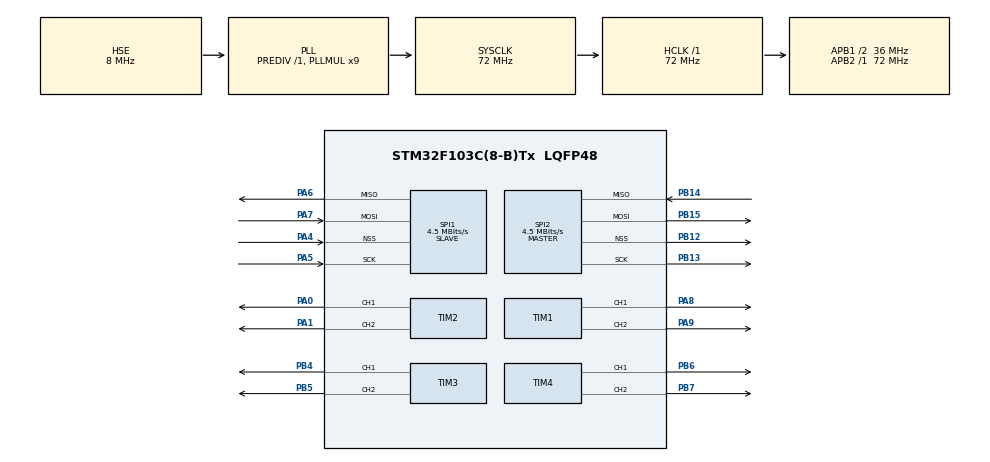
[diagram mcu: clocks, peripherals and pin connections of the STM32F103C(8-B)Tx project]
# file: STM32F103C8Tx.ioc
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Dma.Request0=TIM3_CH1/TRIG
Dma.Request1=TIM4_CH1
Dma.Request2=TIM2_CH1
Dma.Request3=TIM1_CH1
Dma.TIM1_CH1.3.Direction=DMA_MEMORY_TO_PERIPH
Dma.TIM1_CH1.3.Instance=DMA1_Channel2
Dma.TIM1_CH1.3.MemDataAlignment=DMA_MDATAALIGN_BYTE
Dma.TIM1_CH1.3.MemInc=DMA_MINC_ENABLE
Dma.TIM1_CH1.3.Mode=DMA_NORMAL
Dma.TIM1_CH1.3.PeriphDataAlignment=DMA_PDATAALIGN_BYTE
Dma.TIM1_CH1.3.PeriphInc=DMA_PINC_DISABLE
Dma.TIM1_CH1.3.Priority=DMA_PRIORITY_VERY_HIGH
Dma.TIM2_CH1.2.Direction=DMA_MEMORY_TO_PERIPH
Dma.TIM2_CH1.2.Instance=DMA1_Channel5
Dma.TIM2_CH1.2.MemDataAlignment=DMA_MDATAALIGN_BYTE
Dma.TIM2_CH1.2.MemInc=DMA_MINC_ENABLE
Dma.TIM2_CH1.2.Mode=DMA_NORMAL
Dma.TIM2_CH1.2.PeriphDataAlignment=DMA_PDATAALIGN_BYTE
Dma.TIM2_CH1.2.PeriphInc=DMA_PINC_DISABLE
Dma.TIM2_CH1.2.Priority=DMA_PRIORITY_HIGH
Dma.TIM3_CH1/TRIG.0.Direction=DMA_MEMORY_TO_PERIPH
Dma.TIM3_CH1/TRIG.0.Instance=DMA1_Channel6
Dma.TIM3_CH1/TRIG.0.MemDataAlignment=DMA_MDATAALIGN_BYTE
Dma.TIM3_CH1/TRIG.0.MemInc=DMA_MINC_ENABLE
Dma.TIM3_CH1/TRIG.0.Mode=DMA_NORMAL
Dma.TIM3_CH1/TRIG.0.PeriphDataAlignment=DMA_PDATAALIGN_BYTE
Dma.TIM3_CH1/TRIG.0.PeriphInc=DMA_PINC_DISABLE
Dma.TIM3_CH1/TRIG.0.Priority=DMA_PRIORITY_MEDIUM
Dma.TIM4_CH1.1.Direction=DMA_MEMORY_TO_PERIPH
Dma.TIM4_CH1.1.Instance=DMA1_Channel1
Dma.TIM4_CH1.1.MemDataAlignment=DMA_MDATAALIGN_BYTE
Dma.TIM4_CH1.1.MemInc=DMA_MINC_ENABLE
Dma.TIM4_CH1.1.Mode=DMA_NORMAL
Dma.TIM4_CH1.1.PeriphDataAlignment=DMA_PDATAALIGN_BYTE
Dma.TIM4_CH1.1.PeriphInc=DMA_PINC_DISABLE
Dma.TIM4_CH1.1.Priority=DMA_PRIORITY_LOW
Mcu.Family=STM32F1
Mcu.Name=STM32F103C(8-B)Tx
Mcu.Package=LQFP48
NVIC.DMA1_Channel1_IRQn=true\:0\:0\:false\:false\:true\:true
NVIC.DMA1_Channel2_IRQn=true\:0\:0\:false\:false\:true\:true
NVIC.DMA1_Channel5_IRQn=true\:0\:0\:false\:false\:true\:true
NVIC.DMA1_Channel6_IRQn=true\:0\:0\:false\:false\:true\:true
NVIC.PriorityGroup=NVIC_PRIORITYGROUP_4
NVIC.SPI1_IRQn=true\:0\:0\:false\:false\:true\:true
NVIC.SPI2_IRQn=true\:0\:0\:false\:false\:true\:true
PA0-WKUP.Signal=S_TIM2_CH1_ETR
PA1.Signal=S_TIM2_CH2
PA13.Mode=Serial_Wire
PA13.Signal=SYS_JTMS-SWDIO
PA14.Mode=Serial_Wire
PA14.Signal=SYS_JTCK-SWCLK
PA4.GPIO_Mode=GPIO_MODE_INPUT
PA4.GPIO_PuPd=GPIO_NOPULL
PA4.Mode=NSS_Signal_Hard_Input
PA4.Signal=SPI1_NSS
PA5.GPIO_Mode=GPIO_MODE_INPUT
PA5.GPIO_PuPd=GPIO_NOPULL
PA5.Mode=Full_Duplex_Slave
PA5.Signal=SPI1_SCK
PA6.Mode=Full_Duplex_Slave
PA6.Signal=SPI1_MISO
PA7.Mode=Full_Duplex_Slave
PA7.Signal=SPI1_MOSI
PA8.Signal=S_TIM1_CH1
PA9.Signal=S_TIM1_CH2
PB12.Mode=NSS_Signal_Hard_Output
PB12.Signal=SPI2_NSS
PB13.Mode=Full_Duplex_Master
PB13.Signal=SPI2_SCK
PB14.Mode=Full_Duplex_Master
PB14.Signal=SPI2_MISO
PB15.Mode=Full_Duplex_Master
PB15.Signal=SPI2_MOSI
PB4.Signal=S_TIM3_CH1
PB5.Signal=S_TIM3_CH2
PB6.Signal=S_TIM4_CH1
PB7.Signal=S_TIM4_CH2
PD0-OSC_IN.Mode=HSE-External-Oscillator
PD0-OSC_IN.Signal=RCC_OSC_IN
PD1-OSC_OUT.Mode=HSE-External-Oscillator
PD1-OSC_OUT.Signal=RCC_OSC_OUT
ProjectManager.HeapSize=0x200
ProjectManager.StackSize=0x400
ProjectManager.TargetToolchain=SW4STM32
RCC.AHBFreq_Value=72000000
RCC.APB1CLKDivider=RCC_HCLK_DIV2
RCC.APB1Freq_Value=36000000
RCC.APB1TimFreq_Value=72000000
RCC.APB2Freq_Value=72000000
RCC.APB2TimFreq_Value=72000000
RCC.HCLKFreq_Value=72000000
RCC.PLLMUL=RCC_PLL_MUL9
RCC.PLLSourceVirtual=RCC_PLLSOURCE_HSE
RCC.SYSCLKFreq_VALUE=72000000
RCC.SYSCLKSource=RCC_SYSCLKSOURCE_PLLCLK
RCC.USBFreq_Value=72000000
SH.S_TIM1_CH1.0=TIM1_CH1,PWM Generation1 CH1
SH.S_TIM1_CH2.0=TIM1_CH2,Output Compare2 CH2
SH.S_TIM2_CH1_ETR.0=TIM2_CH1,PWM Generation1 CH1
SH.S_TIM2_CH2.0=TIM2_CH2,Output Compare2 CH2
SH.S_TIM3_CH1.0=TIM3_CH1,PWM Generation1 CH1
SH.S_TIM3_CH2.0=TIM3_CH2,Output Compare2 CH2
SH.S_TIM4_CH1.0=TIM4_CH1,PWM Generation1 CH1
SH.S_TIM4_CH2.0=TIM4_CH2,Output Compare2 CH2
SPI1.BaudRatePrescaler=SPI_BAUDRATEPRESCALER_16
SPI1.CalculateBaudRate=4.5 MBits/s
SPI1.Direction=SPI_DIRECTION_2LINES
SPI1.Mode=SPI_MODE_SLAVE
SPI1.VirtualNSS=VM_NSSHARD
SPI1.VirtualType=VM_SLAVE
SPI2.BaudRatePrescaler=SPI_BAUDRATEPRESCALER_8
SPI2.CalculateBaudRate=4.5 MBits/s
SPI2.Direction=SPI_DIRECTION_2LINES
SPI2.Mode=SPI_MODE_MASTER
SPI2.VirtualNSS=VM_NSSHARD
SPI2.VirtualType=VM_MASTER
TIM1.Channel-Output\ Compare2\ CH2=TIM_CHANNEL_2
TIM1.Channel-PWM\ Generation1\ CH1=TIM_CHANNEL_1
TIM1.OCMode_2=TIM_OCMODE_TOGGLE
TIM2.Channel-Output\ Compare2\ CH2=TIM_CHANNEL_2
TIM2.Channel-PWM\ Generation1\ CH1=TIM_CHANNEL_1
TIM2.OCMode_2=TIM_OCMODE_TOGGLE
TIM3.Channel-Output\ Compare2\ CH2=TIM_CHANNEL_2
TIM3.Channel-PWM\ Generation1\ CH1=TIM_CHANNEL_1
TIM3.OCMode_2=TIM_OCMODE_TOGGLE
TIM4.Channel-Output\ Compare2\ CH2=TIM_CHANNEL_2
TIM4.Channel-PWM\ Generation1\ CH1=TIM_CHANNEL_1
TIM4.OCMode_2=TIM_OCMODE_TOGGLE
VP_TIM1_VS_ClockSourceINT.Mode=Internal
VP_TIM2_VS_ClockSourceINT.Mode=Internal
VP_TIM3_VS_ClockSourceINT.Mode=Internal
VP_TIM4_VS_ClockSourceINT.Mode=Internal
board=STM32F103C8Tx

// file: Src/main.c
/**
  ******************************************************************************
  * File Name          : main.c
  * Description        : Main program body
  ******************************************************************************
  ** This notice applies to any and all portions of this file
  * that are not between comment pairs USER CODE BEGIN and
  * USER CODE END. Other portions of this file, whether
  * inserted by the user or by software development tools
  * are owned by their respective copyright owners.
  *
  * COPYRIGHT(c) 2017 STMicroelectronics
  *
  * Redistribution and use in source and binary forms, with or without modification,
  * are permitted provided that the following conditions are met:
  *   1. Redistributions of source code must retain the above copyright notice,
  *      this list of conditions and the following disclaimer.
  *   2. Redistributions in binary form must reproduce the above copyright notice,
  *      this list of conditions and the following disclaimer in the documentation
  *      and/or other materials provided with the distribution.
  *   3. Neither the name of STMicroelectronics nor the names of its contributors
  *      may be used to endorse or promote products derived from this software
  *      without specific prior written permission.
  *
  * THIS SOFTWARE IS PROVIDED BY THE COPYRIGHT HOLDERS AND CONTRIBUTORS "AS IS"
  * AND ANY EXPRESS OR IMPLIED WARRANTIES, INCLUDING, BUT NOT LIMITED TO, THE
  * IMPLIED WARRANTIES OF MERCHANTABILITY AND FITNESS FOR A PARTICULAR PURPOSE ARE
  * DISCLAIMED. IN NO EVENT SHALL THE COPYRIGHT HOLDER OR CONTRIBUTORS BE LIABLE
  * FOR ANY DIRECT, INDIRECT, INCIDENTAL, SPECIAL, EXEMPLARY, OR CONSEQUENTIAL
  * DAMAGES (INCLUDING, BUT NOT LIMITED TO, PROCUREMENT OF SUBSTITUTE GOODS OR
  * SERVICES; LOSS OF USE, DATA, OR PROFITS; OR BUSINESS INTERRUPTION) HOWEVER
  * CAUSED AND ON ANY THEORY OF LIABILITY, WHETHER IN CONTRACT, STRICT LIABILITY,
  * OR TORT (INCLUDING NEGLIGENCE OR OTHERWISE) ARISING IN ANY WAY OUT OF THE USE
  * OF THIS SOFTWARE, EVEN IF ADVISED OF THE POSSIBILITY OF SUCH DAMAGE.
  *
  ******************************************************************************
  */

#include "main.h"
#include "stm32f1xx_hal.h"

/* USER CODE BEGIN Includes */
#include "generator.h"
/* USER CODE END Includes */

SPI_HandleTypeDef hspi1;
SPI_HandleTypeDef hspi2;

TIM_HandleTypeDef htim1;
TIM_HandleTypeDef htim2;
TIM_HandleTypeDef htim3;
TIM_HandleTypeDef htim4;
DMA_HandleTypeDef hdma_tim1_ch1;
DMA_HandleTypeDef hdma_tim2_ch1;
DMA_HandleTypeDef hdma_tim3_ch1_trig;
DMA_HandleTypeDef hdma_tim4_ch1;

void SystemClock_Config(void);
static void MX_GPIO_Init(void);
static void MX_DMA_Init(void);
static void MX_SPI1_Init(void);
static void MX_SPI2_Init(void);
static void MX_TIM1_Init(void);
static void MX_TIM2_Init(void);
static void MX_TIM3_Init(void);
static void MX_TIM4_Init(void);

void HAL_TIM_MspPostInit(TIM_HandleTypeDef *htim);

int main(void)
{

  /* MCU Configuration----------------------------------------------------------*/

  /* Reset of all peripherals, Initializes the Flash interface and the Systick. */
  HAL_Init();

  /* Configure the system clock */
  SystemClock_Config();

  /* USER CODE BEGIN SysInit */
  // init generation core data
  GEN_system_init();
  /* USER CODE END SysInit */

  /* Initialize all configured peripherals */
  MX_GPIO_Init();
  MX_DMA_Init();
  MX_SPI1_Init();
  MX_SPI2_Init();
  MX_TIM1_Init();
  MX_TIM2_Init();
  MX_TIM3_Init();
  MX_TIM4_Init();

  /* USER CODE BEGIN 2 */
  // init generation data
  GEN_init();
  /* USER CODE END 2 */

  /* Infinite loop */
  while (1)
  {

  }

}

/** System Clock Configuration
*/
void SystemClock_Config(void)
{

  RCC_OscInitTypeDef RCC_OscInitStruct;
  RCC_ClkInitTypeDef RCC_ClkInitStruct;

    /**Initializes the CPU, AHB and APB busses clocks
    */
  RCC_OscInitStruct.OscillatorType = RCC_OSCILLATORTYPE_HSE;
  RCC_OscInitStruct.HSEState = RCC_HSE_ON;
  RCC_OscInitStruct.HSEPredivValue = RCC_HSE_PREDIV_DIV1;
  RCC_OscInitStruct.HSIState = RCC_HSI_ON;
  RCC_OscInitStruct.PLL.PLLState = RCC_PLL_ON;
  RCC_OscInitStruct.PLL.PLLSource = RCC_PLLSOURCE_HSE;
  RCC_OscInitStruct.PLL.PLLMUL = RCC_PLL_MUL9;
  if (HAL_RCC_OscConfig(&RCC_OscInitStruct) != HAL_OK)
  {
    _Error_Handler(__FILE__, __LINE__);
  }

    /**Initializes the CPU, AHB and APB busses clocks
    */
  RCC_ClkInitStruct.ClockType = RCC_CLOCKTYPE_HCLK|RCC_CLOCKTYPE_SYSCLK
                              |RCC_CLOCKTYPE_PCLK1|RCC_CLOCKTYPE_PCLK2;
  RCC_ClkInitStruct.SYSCLKSource = RCC_SYSCLKSOURCE_PLLCLK;
  RCC_ClkInitStruct.AHBCLKDivider = RCC_SYSCLK_DIV1;
  RCC_ClkInitStruct.APB1CLKDivider = RCC_HCLK_DIV2;
  RCC_ClkInitStruct.APB2CLKDivider = RCC_HCLK_DIV1;

  if (HAL_RCC_ClockConfig(&RCC_ClkInitStruct, FLASH_LATENCY_2) != HAL_OK)
  {
    _Error_Handler(__FILE__, __LINE__);
  }

    /**Configure the Systick interrupt time
    */
  HAL_SYSTICK_Config(HAL_RCC_GetHCLKFreq()/1000);

    /**Configure the Systick
    */
  HAL_SYSTICK_CLKSourceConfig(SYSTICK_CLKSOURCE_HCLK);

  /* SysTick_IRQn interrupt configuration */
  HAL_NVIC_SetPriority(SysTick_IRQn, 0, 0);
}

/* SPI1 init function */
static void MX_SPI1_Init(void)
{

  /* SPI1 parameter configuration*/
  hspi1.Instance = SPI1;
  hspi1.Init.Mode = SPI_MODE_SLAVE;
  hspi1.Init.Direction = SPI_DIRECTION_2LINES;
  hspi1.Init.DataSize = SPI_DATASIZE_8BIT;
  hspi1.Init.CLKPolarity = SPI_POLARITY_LOW;
  hspi1.Init.CLKPhase = SPI_PHASE_1EDGE;
  hspi1.Init.NSS = SPI_NSS_HARD_INPUT;
  hspi1.Init.BaudRatePrescaler = SPI_BAUDRATEPRESCALER_16;
  hspi1.Init.FirstBit = SPI_FIRSTBIT_MSB;
  hspi1.Init.TIMode = SPI_TIMODE_DISABLE;
  hspi1.Init.CRCCalculation = SPI_CRCCALCULATION_DISABLE;
  hspi1.Init.CRCPolynomial = 10;
  if (HAL_SPI_Init(&hspi1) != HAL_OK)
  {
    _Error_Handler(__FILE__, __LINE__);
  }

}

/* SPI2 init function */
static void MX_SPI2_Init(void)
{

  /* SPI2 parameter configuration*/
  hspi2.Instance = SPI2;
  hspi2.Init.Mode = SPI_MODE_MASTER;
  hspi2.Init.Direction = SPI_DIRECTION_2LINES;
  hspi2.Init.DataSize = SPI_DATASIZE_8BIT;
  hspi2.Init.CLKPolarity = SPI_POLARITY_LOW;
  hspi2.Init.CLKPhase = SPI_PHASE_1EDGE;
  hspi2.Init.NSS = SPI_NSS_HARD_OUTPUT;
  hspi2.Init.BaudRatePrescaler = SPI_BAUDRATEPRESCALER_8;
  hspi2.Init.FirstBit = SPI_FIRSTBIT_MSB;
  hspi2.Init.TIMode = SPI_TIMODE_DISABLE;
  hspi2.Init.CRCCalculation = SPI_CRCCALCULATION_DISABLE;
  hspi2.Init.CRCPolynomial = 10;
  if (HAL_SPI_Init(&hspi2) != HAL_OK)
  {
    _Error_Handler(__FILE__, __LINE__);
  }

}

/* TIM1 init function */
static void MX_TIM1_Init(void)
{

  TIM_ClockConfigTypeDef sClockSourceConfig;
  TIM_MasterConfigTypeDef sMasterConfig;
  TIM_OC_InitTypeDef sConfigOC;
  TIM_BreakDeadTimeConfigTypeDef sBreakDeadTimeConfig;

  htim1.Instance = TIM1;
  htim1.Init.Prescaler = 0;
  htim1.Init.CounterMode = TIM_COUNTERMODE_UP;
  htim1.Init.Period = 0;
  htim1.Init.ClockDivision = TIM_CLOCKDIVISION_DIV1;
  htim1.Init.RepetitionCounter = 0;
  htim1.Init.AutoReloadPreload = TIM_AUTORELOAD_PRELOAD_DISABLE;
  if (HAL_TIM_Base_Init(&htim1) != HAL_OK)
  {
    _Error_Handler(__FILE__, __LINE__);
  }

  sClockSourceConfig.ClockSource = TIM_CLOCKSOURCE_INTERNAL;
  if (HAL_TIM_ConfigClockSource(&htim1, &sClockSourceConfig) != HAL_OK)
  {
    _Error_Handler(__FILE__, __LINE__);
  }

  if (HAL_TIM_PWM_Init(&htim1) != HAL_OK)
  {
    _Error_Handler(__FILE__, __LINE__);
  }

  if (HAL_TIM_OC_Init(&htim1) != HAL_OK)
  {
    _Error_Handler(__FILE__, __LINE__);
  }

  sMasterConfig.MasterOutputTrigger = TIM_TRGO_RESET;
  sMasterConfig.MasterSlaveMode = TIM_MASTERSLAVEMODE_DISABLE;
  if (HAL_TIMEx_MasterConfigSynchronization(&htim1, &sMasterConfig) != HAL_OK)
  {
    _Error_Handler(__FILE__, __LINE__);
  }

  sConfigOC.OCMode = TIM_OCMODE_PWM1;
  sConfigOC.Pulse = 0;
  sConfigOC.OCPolarity = TIM_OCPOLARITY_HIGH;
  sConfigOC.OCNPolarity = TIM_OCNPOLARITY_HIGH;
  sConfigOC.OCFastMode = TIM_OCFAST_DISABLE;
  sConfigOC.OCIdleState = TIM_OCIDLESTATE_RESET;
  sConfigOC.OCNIdleState = TIM_OCNIDLESTATE_RESET;
  if (HAL_TIM_PWM_ConfigChannel(&htim1, &sConfigOC, TIM_CHANNEL_1) != HAL_OK)
  {
    _Error_Handler(__FILE__, __LINE__);
  }

  sConfigOC.OCMode = TIM_OCMODE_TOGGLE;
  if (HAL_TIM_OC_ConfigChannel(&htim1, &sConfigOC, TIM_CHANNEL_2) != HAL_OK)
  {
    _Error_Handler(__FILE__, __LINE__);
  }

  sBreakDeadTimeConfig.OffStateRunMode = TIM_OSSR_DISABLE;
  sBreakDeadTimeConfig.OffStateIDLEMode = TIM_OSSI_DISABLE;
  sBreakDeadTimeConfig.LockLevel = TIM_LOCKLEVEL_OFF;
  sBreakDeadTimeConfig.DeadTime = 0;
  sBreakDeadTimeConfig.BreakState = TIM_BREAK_DISABLE;
  sBreakDeadTimeConfig.BreakPolarity = TIM_BREAKPOLARITY_HIGH;
  sBreakDeadTimeConfig.AutomaticOutput = TIM_AUTOMATICOUTPUT_DISABLE;
  if (HAL_TIMEx_ConfigBreakDeadTime(&htim1, &sBreakDeadTimeConfig) != HAL_OK)
  {
    _Error_Handler(__FILE__, __LINE__);
  }

  HAL_TIM_MspPostInit(&htim1);

}

/* TIM2 init function */
static void MX_TIM2_Init(void)
{

  TIM_ClockConfigTypeDef sClockSourceConfig;
  TIM_MasterConfigTypeDef sMasterConfig;
  TIM_OC_InitTypeDef sConfigOC;

  htim2.Instance = TIM2;
  htim2.Init.Prescaler = 0;
  htim2.Init.CounterMode = TIM_COUNTERMODE_UP;
  htim2.Init.Period = 0;
  htim2.Init.ClockDivision = TIM_CLOCKDIVISION_DIV1;
  htim2.Init.AutoReloadPreload = TIM_AUTORELOAD_PRELOAD_DISABLE;
  if (HAL_TIM_Base_Init(&htim2) != HAL_OK)
  {
    _Error_Handler(__FILE__, __LINE__);
  }

  sClockSourceConfig.ClockSource = TIM_CLOCKSOURCE_INTERNAL;
  if (HAL_TIM_ConfigClockSource(&htim2, &sClockSourceConfig) != HAL_OK)
  {
    _Error_Handler(__FILE__, __LINE__);
  }

  if (HAL_TIM_PWM_Init(&htim2) != HAL_OK)
  {
    _Error_Handler(__FILE__, __LINE__);
  }

  if (HAL_TIM_OC_Init(&htim2) != HAL_OK)
  {
    _Error_Handler(__FILE__, __LINE__);
  }

  sMasterConfig.MasterOutputTrigger = TIM_TRGO_RESET;
  sMasterConfig.MasterSlaveMode = TIM_MASTERSLAVEMODE_DISABLE;
  if (HAL_TIMEx_MasterConfigSynchronization(&htim2, &sMasterConfig) != HAL_OK)
  {
    _Error_Handler(__FILE__, __LINE__);
  }

  sConfigOC.OCMode = TIM_OCMODE_PWM1;
  sConfigOC.Pulse = 0;
  sConfigOC.OCPolarity = TIM_OCPOLARITY_HIGH;
  sConfigOC.OCFastMode = TIM_OCFAST_DISABLE;
  if (HAL_TIM_PWM_ConfigChannel(&htim2, &sConfigOC, TIM_CHANNEL_1) != HAL_OK)
  {
    _Error_Handler(__FILE__, __LINE__);
  }

  sConfigOC.OCMode = TIM_OCMODE_TOGGLE;
  if (HAL_TIM_OC_ConfigChannel(&htim2, &sConfigOC, TIM_CHANNEL_2) != HAL_OK)
  {
    _Error_Handler(__FILE__, __LINE__);
  }

  HAL_TIM_MspPostInit(&htim2);

}

/* TIM3 init function */
static void MX_TIM3_Init(void)
{

  TIM_ClockConfigTypeDef sClockSourceConfig;
  TIM_MasterConfigTypeDef sMasterConfig;
  TIM_OC_InitTypeDef sConfigOC;

  htim3.Instance = TIM3;
  htim3.Init.Prescaler = 0;
  htim3.Init.CounterMode = TIM_COUNTERMODE_UP;
  htim3.Init.Period = 0;
  htim3.Init.ClockDivision = TIM_CLOCKDIVISION_DIV1;
  htim3.Init.AutoReloadPreload = TIM_AUTORELOAD_PRELOAD_DISABLE;
  if (HAL_TIM_Base_Init(&htim3) != HAL_OK)
  {
    _Error_Handler(__FILE__, __LINE__);
  }

  sClockSourceConfig.ClockSource = TIM_CLOCKSOURCE_INTERNAL;
  if (HAL_TIM_ConfigClockSource(&htim3, &sClockSourceConfig) != HAL_OK)
  {
    _Error_Handler(__FILE__, __LINE__);
  }

  if (HAL_TIM_PWM_Init(&htim3) != HAL_OK)
  {
    _Error_Handler(__FILE__, __LINE__);
  }

  if (HAL_TIM_OC_Init(&htim3) != HAL_OK)
  {
    _Error_Handler(__FILE__, __LINE__);
  }

  sMasterConfig.MasterOutputTrigger = TIM_TRGO_RESET;
  sMasterConfig.MasterSlaveMode = TIM_MASTERSLAVEMODE_DISABLE;
  if (HAL_TIMEx_MasterConfigSynchronization(&htim3, &sMasterConfig) != HAL_OK)
  {
    _Error_Handler(__FILE__, __LINE__);
  }

  sConfigOC.OCMode = TIM_OCMODE_PWM1;
  sConfigOC.Pulse = 0;
  sConfigOC.OCPolarity = TIM_OCPOLARITY_HIGH;
  sConfigOC.OCFastMode = TIM_OCFAST_DISABLE;
  if (HAL_TIM_PWM_ConfigChannel(&htim3, &sConfigOC, TIM_CHANNEL_1) != HAL_OK)
  {
    _Error_Handler(__FILE__, __LINE__);
  }

  sConfigOC.OCMode = TIM_OCMODE_TOGGLE;
  if (HAL_TIM_OC_ConfigChannel(&htim3, &sConfigOC, TIM_CHANNEL_2) != HAL_OK)
  {
    _Error_Handler(__FILE__, __LINE__);
  }

  HAL_TIM_MspPostInit(&htim3);

}

/* TIM4 init function */
static void MX_TIM4_Init(void)
{

  TIM_ClockConfigTypeDef sClockSourceConfig;
  TIM_MasterConfigTypeDef sMasterConfig;
  TIM_OC_InitTypeDef sConfigOC;

  htim4.Instance = TIM4;
  htim4.Init.Prescaler = 0;
  htim4.Init.CounterMode = TIM_COUNTERMODE_UP;
  htim4.Init.Period = 0;
  htim4.Init.ClockDivision = TIM_CLOCKDIVISION_DIV1;
  htim4.Init.AutoReloadPreload = TIM_AUTORELOAD_PRELOAD_DISABLE;
  if (HAL_TIM_Base_Init(&htim4) != HAL_OK)
  {
    _Error_Handler(__FILE__, __LINE__);
  }

  sClockSourceConfig.ClockSource = TIM_CLOCKSOURCE_INTERNAL;
  if (HAL_TIM_ConfigClockSource(&htim4, &sClockSourceConfig) != HAL_OK)
  {
    _Error_Handler(__FILE__, __LINE__);
  }

  if (HAL_TIM_PWM_Init(&htim4) != HAL_OK)
  {
    _Error_Handler(__FILE__, __LINE__);
  }

  if (HAL_TIM_OC_Init(&htim4) != HAL_OK)
  {
    _Error_Handler(__FILE__, __LINE__);
  }

  sMasterConfig.MasterOutputTrigger = TIM_TRGO_RESET;
  sMasterConfig.MasterSlaveMode = TIM_MASTERSLAVEMODE_DISABLE;
  if (HAL_TIMEx_MasterConfigSynchronization(&htim4, &sMasterConfig) != HAL_OK)
  {
    _Error_Handler(__FILE__, __LINE__);
  }

  sConfigOC.OCMode = TIM_OCMODE_PWM1;
  sConfigOC.Pulse = 0;
  sConfigOC.OCPolarity = TIM_OCPOLARITY_HIGH;
  sConfigOC.OCFastMode = TIM_OCFAST_DISABLE;
  if (HAL_TIM_PWM_ConfigChannel(&htim4, &sConfigOC, TIM_CHANNEL_1) != HAL_OK)
  {
    _Error_Handler(__FILE__, __LINE__);
  }

  sConfigOC.OCMode = TIM_OCMODE_TOGGLE;
  if (HAL_TIM_OC_ConfigChannel(&htim4, &sConfigOC, TIM_CHANNEL_2) != HAL_OK)
  {
    _Error_Handler(__FILE__, __LINE__);
  }

  HAL_TIM_MspPostInit(&htim4);

}

static void MX_DMA_Init(void)
{
  /* DMA controller clock enable */
  __HAL_RCC_DMA1_CLK_ENABLE();

  /* DMA interrupt init */
  /* DMA1_Channel1_IRQn interrupt configuration */
  HAL_NVIC_SetPriority(DMA1_Channel1_IRQn, 0, 0);
  HAL_NVIC_EnableIRQ(DMA1_Channel1_IRQn);
  /* DMA1_Channel2_IRQn interrupt configuration */
  HAL_NVIC_SetPriority(DMA1_Channel2_IRQn, 0, 0);
  HAL_NVIC_EnableIRQ(DMA1_Channel2_IRQn);
  /* DMA1_Channel5_IRQn interrupt configuration */
  HAL_NVIC_SetPriority(DMA1_Channel5_IRQn, 0, 0);
  HAL_NVIC_EnableIRQ(DMA1_Channel5_IRQn);
  /* DMA1_Channel6_IRQn interrupt configuration */
  HAL_NVIC_SetPriority(DMA1_Channel6_IRQn, 0, 0);
  HAL_NVIC_EnableIRQ(DMA1_Channel6_IRQn);

}

/** Configure pins as
        * Analog
        * Input
        * Output
        * EVENT_OUT
        * EXTI
*/
static void MX_GPIO_Init(void)
{

  /* GPIO Ports Clock Enable */
  __HAL_RCC_GPIOD_CLK_ENABLE();
  __HAL_RCC_GPIOA_CLK_ENABLE();
  __HAL_RCC_GPIOB_CLK_ENABLE();

}

void _Error_Handler(char * file, int line)
{
  while(1)
  {
  }
}

/************************ (C) COPYRIGHT STMicroelectronics *****END OF FILE****/
